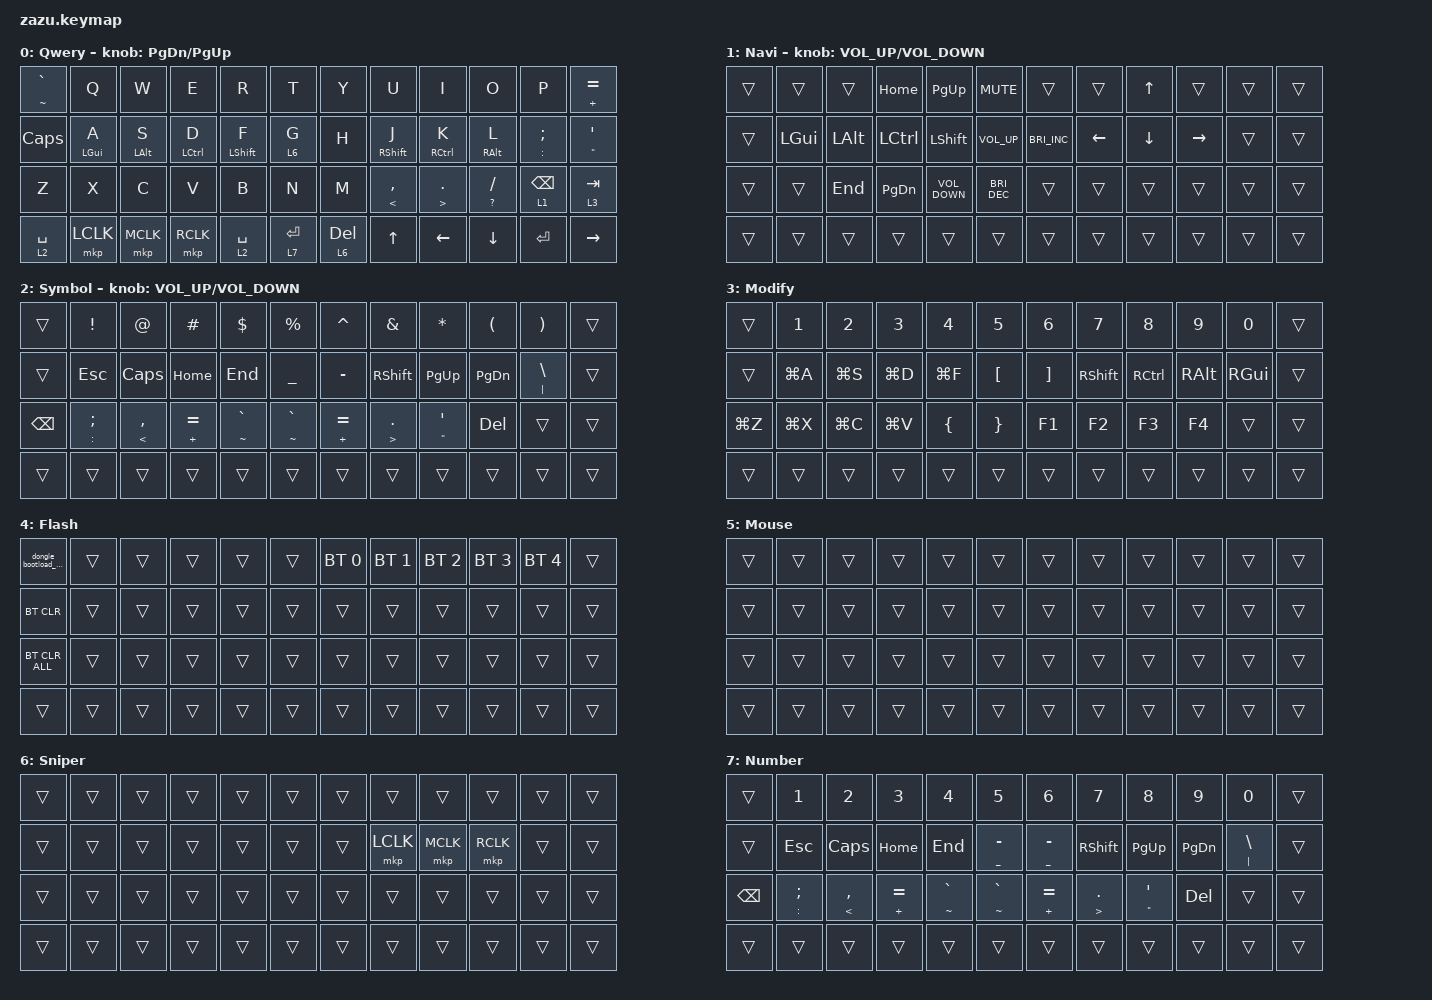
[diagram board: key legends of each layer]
#define ZMK_POINTING_DEFAULT_MOVE_VAL 1200  // 600
#define ZMK_POINTING_DEFAULT_SCRL_VAL 35    // 10
#include <input/processors.dtsi>
#include <behaviors.dtsi>
#include <dt-bindings/zmk/bt.h>
#include <dt-bindings/zmk/keys.h>
#include <dt-bindings/zmk/outputs.h>
#include <dt-bindings/zmk/pointing.h>
#include <dt-bindings/zmk/ext_power.h>
#include <dt-bindings/zmk/rgb.h>
#include <zephyr/dt-bindings/input/input-event-codes.h>
#define SNIPER 6
#define MOUSE 5

/ {
  zip_scroll_scaler: zip_scroll_scaler {
    compatible = "zmk,input-processor-scaler";
    #input-processor-cells = <2>;
    type = <INPUT_EV_REL>;
    codes = <INPUT_REL_WHEEL INPUT_REL_HWHEEL>;
    track-remainders;
  };
};

&mmv_input_listener {
       input-processors = <&zip_xy_scaler 2 1>;
};

&msc_input_listener {
       input-processors = <&zip_scroll_scaler 2 1>;
};

&msc {
    acceleration-exponent = <0>;      // 0
    time-to-max-speed-ms = <0>;       // 300
    delay-ms = <0>;                   // 0
};

&mmv {
    time-to-max-speed-ms = <400>;
    acceleration-exponent = <1>;
};

&trackball_listener {
    scroller {
        layers = <MOUSE>;
        input-processors =
            <&zip_xy_transform INPUT_TRANSFORM_Y_INVERT>,
            <&zip_xy_scaler 1 10>,
            <&zip_xy_to_scroll_mapper>;
    };

    snipe {
        layers = <SNIPER>;
        input-processors = <&zip_xy_scaler 1 3>;
    };
};

/ {
    combos {
        compatible = "zmk,combos";

        combo_esc {
            timeout-ms = <50>;
            key-positions = <0 1>;
            bindings = <&kp ESC>;
        };

        left_bkt {
            bindings = <&kp LEFT_BRACKET>;
            key-positions = <3 4>;
        };

        right_bkt {
            bindings = <&kp RIGHT_BRACKET>;
            key-positions = <7 8>;
        };

        left_brace {
            bindings = <&kp LEFT_BRACE>;
            key-positions = <26 27>;
        };

        right_brace {
            bindings = <&kp RIGHT_BRACE>;
            key-positions = <30 31>;
        };

        less_than {
            bindings = <&kp LEFT_PARENTHESIS>;
            key-positions = <15 16>;
        };

        great_than {
            bindings = <&kp RIGHT_PARENTHESIS>;
            key-positions = <19 20>;
        };

        pipe {
            bindings = <&kp PIPE>;
            key-positions = <5 6>;
        };

        back_slash {
            bindings = <&kp BACKSLASH>;
            key-positions = <17 18>;
        };
    };

    macros {
        dongle_bootload_macro: bootload_macro {
            compatible = "zmk,behavior-macro";
            #binding-cells = <0>;
            bindings = <&bootloader>;
            label = "BOOTLOAD_MACRO";
        };
    };

    behaviors {
        hm: homerow_mods {
            compatible = "zmk,behavior-hold-tap";
            label = "HOMEROW_MODS";
            bindings = <&kp>, <&kp>;

            #binding-cells = <2>;
            tapping-term-ms = <200>;
            quick-tap-ms = <180>;
            flavor = "tap-preferred";
        };

        ltq: ltq {
            compatible = "zmk,behavior-hold-tap";
            label = "LTQ";
            bindings = <&mo>, <&kp>;

            #binding-cells = <2>;
            tapping-term-ms = <200>;
            quick-tap-ms = <180>;
        };

        as: auto_shift {
            compatible = "zmk,behavior-hold-tap";
            label = "AUTO_SHIFT";
            bindings = <&kp>, <&kp>;

            #binding-cells = <2>;
            tapping-term-ms = <135>;
            quick-tap-ms = <0>;
        };

        scroll_encoder: scroll_encoder {
            compatible = "zmk,behavior-sensor-rotate";
            #sensor-binding-cells = <0>;
            bindings = <&msc SCRL_UP>, <&msc SCRL_DOWN>;

            tap-ms = <30>;
        };
    };

    keymap {
        compatible = "zmk,keymap";

        Qwery {
            bindings = <
&as TILDE GRAVE  &kp Q           &kp W           &kp E               &kp R             &kp T         &kp Y          &kp U                &kp I                    &kp O               &kp P                &as PLUS EQUAL
&kp CAPSLOCK     &hm LEFT_GUI A  &hm LEFT_ALT S  &hm LEFT_CONTROL D  &hm LEFT_SHIFT F  &lt 6 G       &kp H          &hm RIGHT_SHIFT J    &hm RIGHT_CONTROL K      &hm RIGHT_ALT L     &as COLON SEMICOLON  &as DOUBLE_QUOTES SINGLE_QUOTE
&kp Z            &kp X           &kp C           &kp V               &kp B             &kp N         &kp M          &as LESS_THAN COMMA  &as GREATER_THAN PERIOD  &as QUESTION SLASH  &ltq 1 BACKSPACE     &ltq 3 TAB
&ltq 2 SPACE     &mkp LCLK       &mkp MCLK       &mkp RCLK           &ltq 2 SPACE      &ltq 7 ENTER  &ltq 6 DELETE  &kp UP_ARROW         &kp LEFT_ARROW           &kp DOWN_ARROW      &kp ENTER            &kp RIGHT_ARROW
            >;

            sensor-bindings = <&inc_dec_kp PAGE_DOWN PAGE_UP>;
            label = "Qwery";
        };

        Navi {
            bindings = <
&trans  &trans        &trans        &kp HOME          &kp PAGE_UP        &kp K_MUTE            &trans                &trans    &kp UP_ARROW    &trans           &trans  &trans
&trans  &kp LEFT_GUI  &kp LEFT_ALT  &kp LEFT_CONTROL  &kp LEFT_SHIFT     &kp C_VOLUME_UP       &kp C_BRIGHTNESS_INC  &kp LEFT  &kp DOWN_ARROW  &kp RIGHT_ARROW  &trans  &trans
&trans  &trans        &kp END       &kp PAGE_DOWN     &kp C_VOLUME_DOWN  &kp C_BRIGHTNESS_DEC  &trans                &trans    &trans          &trans           &trans  &trans
&trans  &trans        &trans        &trans            &trans             &trans                &trans                &trans    &trans          &trans           &trans  &trans
            >;

            sensor-bindings = <&inc_dec_kp C_VOLUME_UP C_VOLUME_DOWN>;
            label = "Navi";
        };

        Symbol {
            bindings = <
&trans         &kp EXCLAMATION      &kp AT_SIGN          &kp HASH        &kp DOLLAR       &kp PERCENT      &kp CARET       &kp AMPERSAND            &kp ASTERISK                    &kp LEFT_PARENTHESIS  &kp RIGHT_PARENTHESIS  &trans
&trans         &kp ESC              &kp CAPS             &kp HOME        &kp END          &kp UNDERSCORE   &kp MINUS       &kp RIGHT_SHIFT          &kp PAGE_UP                     &kp PAGE_DOWN         &as PIPE BACKSLASH     &trans
&kp BACKSPACE  &as COLON SEMICOLON  &as LESS_THAN COMMA  &as PLUS EQUAL  &as TILDE GRAVE  &as TILDE GRAVE  &as PLUS EQUAL  &as GREATER_THAN PERIOD  &as DOUBLE_QUOTES SINGLE_QUOTE  &kp DELETE            &trans                 &trans
&trans         &trans               &trans               &trans          &trans           &trans           &trans          &trans                   &trans                          &trans                &trans                 &trans
            >;

            sensor-bindings = <&inc_dec_kp C_VOLUME_UP C_VOLUME_DOWN>;
            label = "Symbol";
        };

        Modify {
            bindings = <
&trans     &kp NUMBER_1  &kp NUMBER_2  &kp NUMBER_3  &kp NUMBER_4    &kp NUMBER_5      &kp NUMBER_6       &kp N7           &kp N8             &kp N9         &kp N0         &trans
&trans     &kp LG(A)     &kp LG(S)     &kp LG(D)     &kp LG(F)       &kp LEFT_BRACKET  &kp RIGHT_BRACKET  &kp RIGHT_SHIFT  &kp RIGHT_CONTROL  &kp RIGHT_ALT  &kp RIGHT_GUI  &trans
&kp LG(Z)  &kp LG(X)     &kp LG(C)     &kp LG(V)     &kp LEFT_BRACE  &kp RIGHT_BRACE   &kp F1             &kp F2           &kp F3             &kp F4         &trans         &trans
&trans     &trans        &trans        &trans        &trans          &trans            &trans             &trans           &trans             &trans         &trans         &trans
            >;

            label = "Modify";
        };

        Flash {
            bindings = <
&dongle_bootload_macro  &trans  &trans  &trans  &trans  &trans  &bt BT_SEL 0  &bt BT_SEL 1  &bt BT_SEL 2  &bt BT_SEL 3  &bt BT_SEL 4  &trans
&bt BT_CLR              &trans  &trans  &trans  &trans  &trans  &trans        &trans        &trans        &trans        &trans        &trans
&bt BT_CLR_ALL          &trans  &trans  &trans  &trans  &trans  &trans        &trans        &trans        &trans        &trans        &trans
&trans                  &trans  &trans  &trans  &trans  &trans  &trans        &trans        &trans        &trans        &trans        &trans
            >;

            label = "Flash";
        };

        Mouse {
            bindings = <
&trans  &trans  &trans  &trans  &trans  &trans  &trans  &trans  &trans  &trans  &trans  &trans
&trans  &trans  &trans  &trans  &trans  &trans  &trans  &trans  &trans  &trans  &trans  &trans
&trans  &trans  &trans  &trans  &trans  &trans  &trans  &trans  &trans  &trans  &trans  &trans
&trans  &trans  &trans  &trans  &trans  &trans  &trans  &trans  &trans  &trans  &trans  &trans
            >;

            label = "Mouse";
        };

        Sniper {
            bindings = <
&trans  &trans  &trans  &trans  &trans  &trans  &trans  &trans     &trans     &trans     &trans  &trans
&trans  &trans  &trans  &trans  &trans  &trans  &trans  &mkp LCLK  &mkp MCLK  &mkp RCLK  &trans  &trans
&trans  &trans  &trans  &trans  &trans  &trans  &trans  &trans     &trans     &trans     &trans  &trans
&trans  &trans  &trans  &trans  &trans  &trans  &trans  &trans     &trans     &trans     &trans  &trans
            >;

            label = "Sniper";
        };

        Number {
            bindings = <
&trans         &kp NUMBER_1         &kp NUMBER_2         &kp NUMBER_3    &kp NUMBER_4     &kp NUMBER_5          &kp NUMBER_6          &kp NUMBER_7             &kp NUMBER_8           &kp NUMBER_9   &kp NUMBER_0        &trans
&trans         &kp ESCAPE           &kp CAPS             &kp HOME        &kp END          &as UNDERSCORE MINUS  &as UNDERSCORE MINUS  &kp RIGHT_SHIFT          &kp PAGE_UP            &kp PAGE_DOWN  &as PIPE BACKSLASH  &trans
&kp BACKSPACE  &as COLON SEMICOLON  &as LESS_THAN COMMA  &as PLUS EQUAL  &as TILDE GRAVE  &as TILDE GRAVE       &as PLUS EQUAL        &as GREATER_THAN PERIOD  &as DOUBLE_QUOTES SQT  &kp DELETE     &trans              &trans
&trans         &trans               &trans               &trans          &trans           &trans                &trans                &trans                   &trans                 &trans         &trans              &trans
            >;

            label = "Number";
        };
    };

    conditional_layers {
        compatible = "zmk,conditional-layers";

        flash {
            if-layers = <2 3>;
            then-layer = <4>;
        };
    };
};
